# ATSAMA5D34 register map
Vendor: Microchip Technology; Series: SAMA5D3; File version: 0
Registers are 32-bit, read-write, reset 0x0 unless marked. A register's access mark holds for its fields unless they carry their own. Offsets are from the block's base; [hi:lo] are bit positions; {n}, {i} and the like mark numbered series.

## MPDDRC — AHB Multi-port DDR-SDRAM Controller
Base 0xFFFFEA00
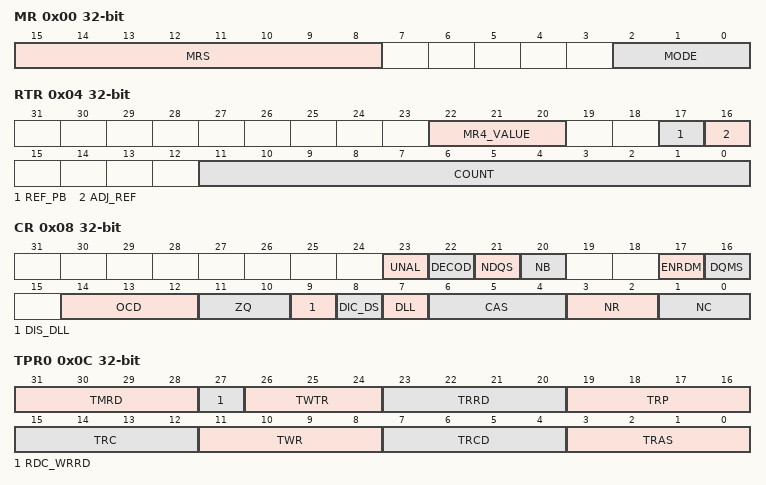
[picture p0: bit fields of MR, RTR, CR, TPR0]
0x00 MR — MPDDRC Mode Register
  [15:8] MRS — Mode Register Select LPDDR2
  [2:0] MODE — MPDDRC Command Mode
    0=NORMAL_CMD (Normal Mode. Any access to the MPDDRC is decoded normally. To activate this mode, the command must be followed by a write to the DDR-SDRAM.); 1=NOP_CMD (The MPDDRC issues a NOP command when the DDR-SDRAM device is accessed regardless of the cycle. To activate this mode, the command must be followed by a write to the DDR-SDRAM.); 2=PRCGALL_CMD (The MPDDRC issues the All Banks Precharge command when the DDR-SDRAM device is accessed regardless of the cycle. To activate this mode, the command must be followed by a write to the SDRAM.); 3=LMR_CMD (The MPDDRC issues a Load Mode Register command when the DDR-SDRAM device is accessed regardless of the cycle. To activate this mode, the command must be followed by a write to the DDR-SDRAM.); 4=RFSH_CMD (The MPDDRC issues an Auto-Refresh command when the DDR-SDRAM device is accessed regardless of the cycle. Previously, an All Banks Precharge command must be issued. To activate this mode, the command must be followed by a write to the DDR-SDRAM.); 5=EXT_LMR_CMD (The MPDDRC issues an Extended Load Mode Register command when the SDRAM device is accessed regardless of the cycle. To activate this mode, the command must be followed by a write to the DDR-SDRAM. The write in the DDR-SDRAM must be done in the appropriate bank.); 6=DEEP_MD (Deep Power mode: Access to Deep Power-down mode); 7=LPDDR2_CMD (The MPDDRC issues an LPDDR2 Mode Register command when the device is accessed regardless of the cycle. To activate this mode, the Mode Register command must be followed by a write to the low-power DDR2-SDRAM.)
0x04 RTR — MPDDRC Refresh Timer Register
  [22:20] MR4_VALUE — Content of MR4 Register
  [17] REF_PB — Refresh Per Bank
  [16] ADJ_REF — Adjust Refresh Rate
  [11:0] COUNT — MPDDRC Refresh Timer Count
0x08 CR — MPDDRC Configuration Register
  [23] UNAL — Support Unaligned Access
    0=UNSUPPORTED (Unaligned access is not supported.); 1=SUPPORTED (Unaligned access is supported.)
  [22] DECOD — Type of Decoding
    0=SEQUENTIAL (Method for address mapping where banks alternate at each last DDR-SDRAM page of the current bank.); 1=INTERLEAVED (Method for address mapping where banks alternate at each SDRAM end page of the current bank.)
  [21] NDQS — Not DQS
    0=ENABLED (Not DQS is enabled); 1=DISABLED (Not DQS is disabled)
  [20] NB — Number of Banks
    0=_4_BANKS (4-bank memory devices); 1=_8_BANKS (8 banks. Only possible when using the DDR2-SDRAM and low-power DDR2-SDRAM devices.)
  [17] ENRDM — Enable Read Measure
    0=OFF (DQS/DDR_DATA phase error correction is disabled); 1=ON (DQS/DDR_DATA phase error correction is enabled)
  [16] DQMS — Mask Data is Shared
    0=NOT_SHARED (DQM is not shared with another controller); 1=SHARED (DQM is shared with another controller)
  [14:12] OCD — Off-chip Driver
    0=DDR2_EXITCALIB (Exit from OCD Calibration mode and maintain settings); 7=DDR2_DEFAULT_CALIB (OCD calibration default)
  [11:10] ZQ — ZQ Calibration
    0=INIT (Calibration command after initialization); 1=LONG (Long calibration); 2=SHORT (Short calibration); 3=RESET (ZQ Reset)
  [9] DIS_DLL — DISABLE DLL
  [8] DIC_DS — Output Driver Impedance Control (Drive Strength)
    0=DDR2_NORMALSTRENGTH (Normal drive strength (DDR2)); 1=DDR2_WEAKSTRENGTH (Weak drive strength (DDR2))
  [7] DLL — Reset DLL
    0=RESET_DISABLED (Disable DLL reset); 1=RESET_ENABLED (Enable DLL reset)
  [6:4] CAS — CAS Latency
    2=DDR_CAS2 (LPDDR1 CAS Latency 2); 3=DDR_CAS3 (DDR2/LPDDR2/LPDDR1 CAS Latency 3)
  [3:2] NR — Number of Row Bits
    0=_11_ROW_BITS (11 bits to define the row number, up to 2048 rows); 1=_12_ROW_BITS (12 bits to define the row number, up to 4096 rows); 2=_13_ROW_BITS (13 bits to define the row number, up to 8192 rows); 3=_14_ROW_BITS (14 bits to define the row number, up to 16384 rows)
  [1:0] NC — Number of Column Bits
    {v}=DDR{v+9}_MDDR{v+8}_COL_BITS ({v+9} bits for DDR, {v+8}-bit for low-power DDR1-SDRAM) (v=0..3)
0x0C TPR0 — MPDDRC Timing Parameter 0 Register
  [31:28] TMRD — Load Mode Register Command to Activate or Refresh Command
  [27] RDC_WRRD — Reduce Write to Read Delay
  [26:24] TWTR — Internal Write to Read Delay
  [23:20] TRRD — Active BankA to Active BankB
  [19:16] TRP — Row Precharge Delay
  [15:12] TRC — Row Cycle Delay
  [11:8] TWR — Write Recovery Delay
  [7:4] TRCD — Row to Column Delay
  [3:0] TRAS — Active to Precharge Delay
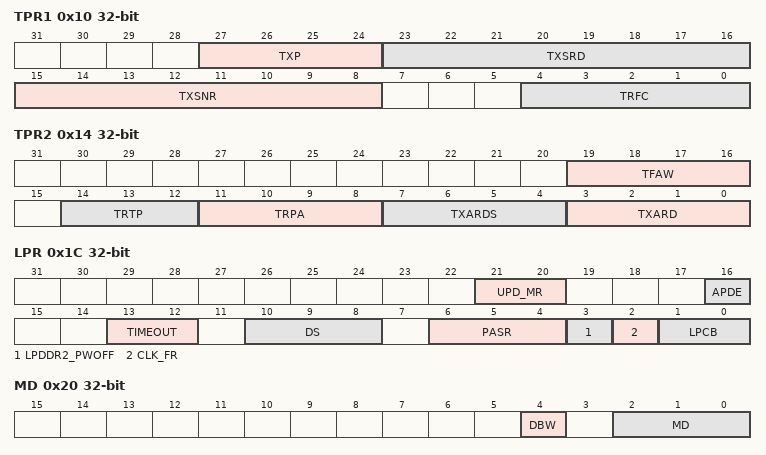
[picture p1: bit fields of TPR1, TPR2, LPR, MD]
0x10 TPR1 — MPDDRC Timing Parameter 1 Register
  [27:24] TXP — Exit Power-down Delay to First Command
  [23:16] TXSRD — Exit Self-refresh Delay to Read Command
  [15:8] TXSNR — Exit Self-refresh Delay to Non-Read Command
  [4:0] TRFC — Row Cycle Delay
0x14 TPR2 — MPDDRC Timing Parameter 2 Register
  [19:16] TFAW — Four Active Windows
  [14:12] TRTP — Read to Precharge
  [11:8] TRPA — Row Precharge All Delay
  [7:4] TXARDS — Exit Active Power Down Delay to Read Command in Mode 'Slow Exit'
  [3:0] TXARD — Exit Active Power Down Delay to Read Command in Mode 'Fast Exit'
0x1C LPR — MPDDRC Low-power Register
  [21:20] UPD_MR — Update Load Mode Register and Extended Mode Register
    0=NO_UPDATE (Update of Load Mode and Extended Mode registers is disabled.); 1=UPDATE_SHAREDBUS (MPDDRC shares an external bus. Automatic update is done during a refresh command and a pending read or write access in the SDRAM device.); 2=UPDATE_NOSHAREDBUS (MPDDRC does not share an external bus. Automatic update is done before entering Self-refresh mode.)
  [16] APDE — Active Power Down Exit Time
    0=DDR2_FAST_EXIT (Fast Exit from Power Down. DDR2-SDRAM devices only.); 1=DDR2_SLOW_EXIT (Slow Exit from Power Down. DDR2-SDRAM devices only.)
  [13:12] TIMEOUT — Time Between Last Transfer and Low-Power Mode
    0=NONE (SDRAM Low-power mode is activated immediately after the end of the last transfer.); 1=DELAY_64_CLK (SDRAM Low-power mode is activated 64 clock cycles after the end of the last transfer.); 2=DELAY_128_CLK (SDRAM Low-power mode is activated 128 clock cycles after the end of the last transfer.)
  [10:8] DS — Drive Strength
    0=DS_FULL (Full drive strength); 1=DS_HALF (Half drive strength); 2=DS_QUARTER (Quarter drive strength); 3=DS_OCTANT (Octant drive strength)
  [6:4] PASR — Partial Array Self-refresh
  [3] LPDDR2_PWOFF — LPDDR2 - LPDDR3 Power Off Bit
    0=DISABLED (No power-off sequence applied to LPDDR2.); 1=ENABLED (A power-off sequence is applied to the LPDDR2 device. CKE is forced low.)
  [2] CLK_FR — Clock Frozen Command Bit
    0=DISABLED (Clock(s) is/are not frozen.); 1=ENABLED (Clock(s) is/are frozen.)
  [1:0] LPCB — Low-power Command Bit
    0=NOLOWPOWER (Low-power feature is inhibited. No Power-down, Self-refresh and Deep-power modes are issued to the DDR-SDRAM device.); 1=SELFREFRESH (The MPDDRC issues a self-refresh command to the DDR-SDRAM device, the clock(s) is/are deactivated and the CKE signal is set low. The DDR-SDRAM device leaves the Self-refresh mode when accessed and reenters it after the access.); 2=POWERDOWN (The MPDDRC issues a Power-down command to the DDR-SDRAM device after each access, the CKE signal is set low. The DDR-SDRAM device leaves the Power-down mode when accessed and reenters it after the access.); 3=DEEPPOWERDOWN (The MPDDRC issues a Deep Power-down command to the low-power DDR-SDRAM device.)
0x20 MD — MPDDRC Memory Device Register
  [4] DBW — Data Bus Width
    0=DBW_32_BITS (Data bus width is 32 bits)
  [2:0] MD — Memory Device
    3=LPDDR_SDRAM (Low-power DDR1-SDRAM); 6=DDR2_SDRAM; 7=LPDDR2_SDRAM (Low-power DDR2-SDRAM)
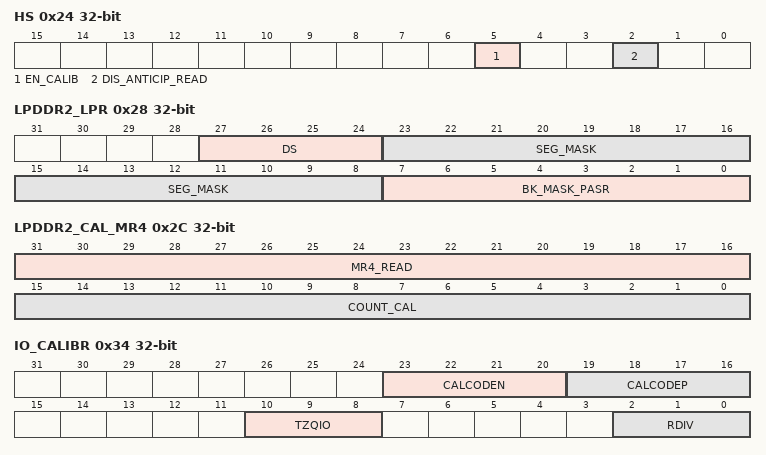
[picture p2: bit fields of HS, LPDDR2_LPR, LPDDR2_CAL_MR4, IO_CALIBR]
0x24 HS — MPDDRC High Speed Register
  [5] EN_CALIB — Enable of the Calibration
    0=DISABLE_CALIBRATION (Calibration is disabled.); 1=ENABLE_CALIBRATION (Calibration is enabled.)
  [2] DIS_ANTICIP_READ — Disable Anticip Read Access
0x28 LPDDR2_LPR — MPDDRC LPDDR2 Low-power Register
  [27:24] DS — Drive Strength
    1=DS_34_3 (34.3 ohm typical); 2=40 ohm typical (default); 3=48 ohm typical; 4=60 ohm typical; 6=80 ohm typical; 7=120 ohm typical
  [23:8] SEG_MASK — Segment Mask Bit
  [7:0] BK_MASK_PASR — Bank Mask Bit/PASR
0x2C LPDDR2_CAL_MR4 — MPDDRC Low-power DDR2 Calibration and MR4 Register
  [31:16] MR4_READ — Mode Register 4 Read Interval
  [15:0] COUNT_CAL — LPDDR2Calibration Timer Count
0x30 LPDDR2_TIM_CAL — MPDDRC Low-power DDR2 Timing Calibration Register
  [7:0] ZQCS — ZQ Calibration Short
0x34 IO_CALIBR — MPDDRC IO Calibration
  [23:20] CALCODEN — Number of Transistor N
  [19:16] CALCODEP — Number of Transistor P
  [10:8] TZQIO — IO Calibration
  [2:0] RDIV — Resistor Divider, Output Driver Impedance
    1=RZQ_34 (LP-DDR2 serial impedance line = 34.3 ohms,DDR2/LP-DDR1 serial impedance line: Not applicable); 2=RZQ_40_RZQ_33_3 (LP-DDR2 serial impedance line = 40 ohms,DDR2/LP-DDR1 serial impedance line = 33.3 ohms); 3=RZQ_48_RZQ_40 (LP-DDR2 serial impedance line = 48 ohms,DDR2/LP-DDR1 serial impedance line = 40 ohms); 4=RZQ_60_RZQ_50 (LP-DDR2 serial impedance line = 60 ohms,DDR2/LP-DDR1 serial impedance line = 50 ohms); 6=RZQ_80_RZQ_66_7 (LP-DDR2 serial impedance line = 80 ohms,DDR2/LP-DDR1 serial impedance line = 66.7 ohms); 7=RZQ_120_RZQ_100 (LP-DDR2 serial impedance line = 120 ohms,DDR2/LP-DDR1 serial impedance line = 100 ohms)
0x38 OCMS — MPDDRC OCMS Register
  [0] SCR_EN — Scrambling Enable
0x3C OCMS_KEY1 wo — MPDDRC OCMS KEY1 Register
  [31:0] KEY1 — Off-chip Memory Scrambling (OCMS) Key Part 1
0x40 OCMS_KEY2 wo — MPDDRC OCMS KEY2 Register
  [31:0] KEY2 — Off-chip Memory Scrambling (OCMS) Key Part 2
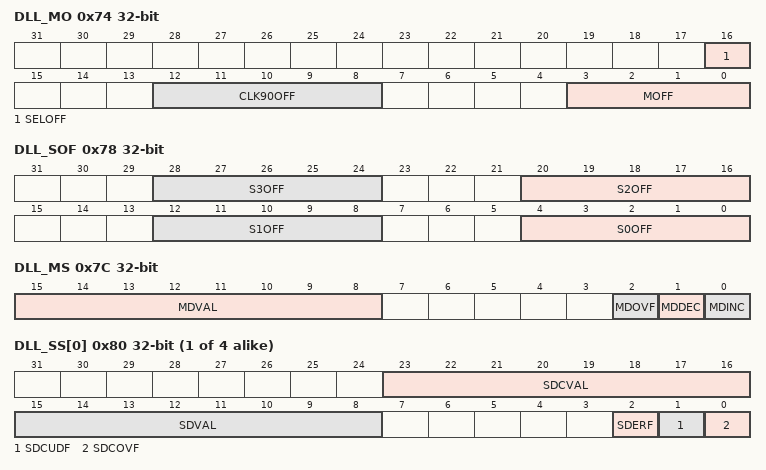
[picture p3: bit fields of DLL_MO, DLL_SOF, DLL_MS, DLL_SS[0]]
0x74 DLL_MO — MPDDRC DLL Master Offset Register
  [16] SELOFF — DLL Offset Selection
  [12:8] CLK90OFF — DLL CLK90 Delay Line Offset
  [3:0] MOFF — DLL Master Delay Line Offset
0x78 DLL_SOF — MPDDRC DLL Slave Offset Register
  [8n+4:8n] S{n}OFF (n=0..3) — DLL Slave {n} Delay Line Offset ([x = 0..3])
0x7C DLL_MS ro — MPDDRC DLL Status Master Register
  [15:8] MDVAL — DLL Master Delay Value
  [2] MDOVF — DLL Master Delay Overflow Flag
  [1] MDDEC — DLL Master Delay Decrement
  [0] MDINC — DLL Master Delay Increment
{0x80+4i} DLL_SS[{i}] (i=0..3) ro — MPDDRC DLL Status Slave 0 Register
  [23:16] SDCVAL — DLL Slave x Delay Correction Value
  [15:8] SDVAL — DLL Slave x Delay Value
  [2] SDERF — DLL Slave x Delay Correction Error Flag
  [1] SDCUDF — DLL Slave x Delay Correction Underflow Flag
  [0] SDCOVF — DLL Slave x Delay Correction Overflow Flag
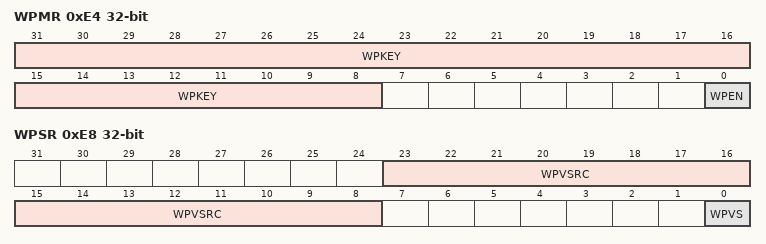
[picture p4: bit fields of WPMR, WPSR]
0xE4 WPMR — MPDDRC Write Protection Mode Register
  [31:8] WPKEY — Write Protection Key
    0x444452=PASSWD (Writing any other value in this field aborts the write operation of the WPEN bit.Always reads as 0.)
  [0] WPEN — Write Protection Enable
0xE8 WPSR ro — MPDDRC Write Protection Status Register
  [23:8] WPVSRC — Write Protection Violation Source
  [0] WPVS — Write Protection Enable
